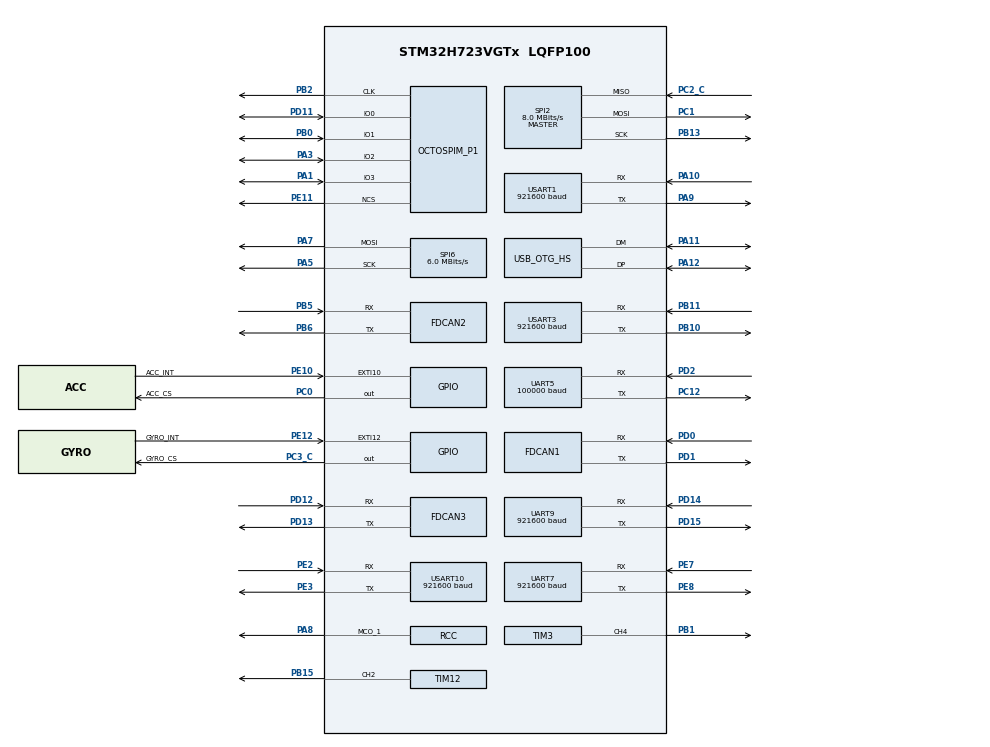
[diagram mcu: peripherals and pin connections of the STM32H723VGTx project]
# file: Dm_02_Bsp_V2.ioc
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CORTEX_M7.CPU_ICache=Enabled
CORTEX_M7.default_mode_Activation=0
Dma.Request0=UART5_RX
Dma.Request1=SPI2_RX
Dma.Request2=SPI2_TX
Dma.Request3=UART9_TX
Dma.Request4=UART9_RX
Dma.Request5=USART1_RX
Dma.Request6=USART1_TX
Dma.SPI2_RX.1.Direction=DMA_PERIPH_TO_MEMORY
Dma.SPI2_RX.1.EventEnable=DISABLE
Dma.SPI2_RX.1.FIFOMode=DMA_FIFOMODE_DISABLE
Dma.SPI2_RX.1.Instance=DMA1_Stream1
Dma.SPI2_RX.1.MemDataAlignment=DMA_MDATAALIGN_BYTE
Dma.SPI2_RX.1.MemInc=DMA_MINC_ENABLE
Dma.SPI2_RX.1.Mode=DMA_NORMAL
Dma.SPI2_RX.1.PeriphDataAlignment=DMA_PDATAALIGN_BYTE
Dma.SPI2_RX.1.PeriphInc=DMA_PINC_DISABLE
Dma.SPI2_RX.1.Polarity=HAL_DMAMUX_REQ_GEN_RISING
Dma.SPI2_RX.1.Priority=DMA_PRIORITY_VERY_HIGH
Dma.SPI2_RX.1.RequestNumber=1
Dma.SPI2_RX.1.SignalID=NONE
Dma.SPI2_RX.1.SyncEnable=DISABLE
Dma.SPI2_RX.1.SyncPolarity=HAL_DMAMUX_SYNC_NO_EVENT
Dma.SPI2_RX.1.SyncRequestNumber=1
Dma.SPI2_RX.1.SyncSignalID=NONE
Dma.SPI2_TX.2.Direction=DMA_MEMORY_TO_PERIPH
Dma.SPI2_TX.2.EventEnable=DISABLE
Dma.SPI2_TX.2.FIFOMode=DMA_FIFOMODE_DISABLE
Dma.SPI2_TX.2.Instance=DMA1_Stream2
Dma.SPI2_TX.2.MemDataAlignment=DMA_MDATAALIGN_BYTE
Dma.SPI2_TX.2.MemInc=DMA_MINC_ENABLE
Dma.SPI2_TX.2.Mode=DMA_NORMAL
Dma.SPI2_TX.2.PeriphDataAlignment=DMA_PDATAALIGN_BYTE
Dma.SPI2_TX.2.PeriphInc=DMA_PINC_DISABLE
Dma.SPI2_TX.2.Polarity=HAL_DMAMUX_REQ_GEN_RISING
Dma.SPI2_TX.2.Priority=DMA_PRIORITY_VERY_HIGH
Dma.SPI2_TX.2.RequestNumber=1
Dma.SPI2_TX.2.SignalID=NONE
Dma.SPI2_TX.2.SyncEnable=DISABLE
Dma.SPI2_TX.2.SyncPolarity=HAL_DMAMUX_SYNC_NO_EVENT
Dma.SPI2_TX.2.SyncRequestNumber=1
Dma.SPI2_TX.2.SyncSignalID=NONE
Dma.UART5_RX.0.Direction=DMA_PERIPH_TO_MEMORY
Dma.UART5_RX.0.EventEnable=DISABLE
Dma.UART5_RX.0.FIFOMode=DMA_FIFOMODE_DISABLE
Dma.UART5_RX.0.Instance=DMA1_Stream0
Dma.UART5_RX.0.MemDataAlignment=DMA_MDATAALIGN_BYTE
Dma.UART5_RX.0.MemInc=DMA_MINC_ENABLE
Dma.UART5_RX.0.Mode=DMA_NORMAL
Dma.UART5_RX.0.PeriphDataAlignment=DMA_PDATAALIGN_BYTE
Dma.UART5_RX.0.PeriphInc=DMA_PINC_DISABLE
Dma.UART5_RX.0.Polarity=HAL_DMAMUX_REQ_GEN_RISING
Dma.UART5_RX.0.Priority=DMA_PRIORITY_VERY_HIGH
Dma.UART5_RX.0.RequestNumber=1
Dma.UART5_RX.0.SignalID=NONE
Dma.UART5_RX.0.SyncEnable=DISABLE
Dma.UART5_RX.0.SyncPolarity=HAL_DMAMUX_SYNC_NO_EVENT
Dma.UART5_RX.0.SyncRequestNumber=1
Dma.UART5_RX.0.SyncSignalID=NONE
Dma.UART9_RX.4.Direction=DMA_PERIPH_TO_MEMORY
Dma.UART9_RX.4.EventEnable=DISABLE
Dma.UART9_RX.4.FIFOMode=DMA_FIFOMODE_DISABLE
Dma.UART9_RX.4.Instance=DMA1_Stream4
Dma.UART9_RX.4.MemDataAlignment=DMA_MDATAALIGN_BYTE
Dma.UART9_RX.4.MemInc=DMA_MINC_ENABLE
Dma.UART9_RX.4.Mode=DMA_NORMAL
Dma.UART9_RX.4.PeriphDataAlignment=DMA_PDATAALIGN_BYTE
Dma.UART9_RX.4.PeriphInc=DMA_PINC_DISABLE
Dma.UART9_RX.4.Polarity=HAL_DMAMUX_REQ_GEN_RISING
Dma.UART9_RX.4.Priority=DMA_PRIORITY_HIGH
Dma.UART9_RX.4.RequestNumber=1
Dma.UART9_RX.4.SignalID=NONE
Dma.UART9_RX.4.SyncEnable=DISABLE
Dma.UART9_RX.4.SyncPolarity=HAL_DMAMUX_SYNC_NO_EVENT
Dma.UART9_RX.4.SyncRequestNumber=1
Dma.UART9_RX.4.SyncSignalID=NONE
Dma.UART9_TX.3.Direction=DMA_MEMORY_TO_PERIPH
Dma.UART9_TX.3.EventEnable=DISABLE
Dma.UART9_TX.3.FIFOMode=DMA_FIFOMODE_DISABLE
Dma.UART9_TX.3.Instance=DMA1_Stream3
Dma.UART9_TX.3.MemDataAlignment=DMA_MDATAALIGN_BYTE
Dma.UART9_TX.3.MemInc=DMA_MINC_ENABLE
Dma.UART9_TX.3.Mode=DMA_NORMAL
Dma.UART9_TX.3.PeriphDataAlignment=DMA_PDATAALIGN_BYTE
Dma.UART9_TX.3.PeriphInc=DMA_PINC_DISABLE
Dma.UART9_TX.3.Polarity=HAL_DMAMUX_REQ_GEN_RISING
Dma.UART9_TX.3.Priority=DMA_PRIORITY_HIGH
Dma.UART9_TX.3.RequestNumber=1
Dma.UART9_TX.3.SignalID=NONE
Dma.UART9_TX.3.SyncEnable=DISABLE
Dma.UART9_TX.3.SyncPolarity=HAL_DMAMUX_SYNC_NO_EVENT
Dma.UART9_TX.3.SyncRequestNumber=1
Dma.UART9_TX.3.SyncSignalID=NONE
Dma.USART1_RX.5.Direction=DMA_PERIPH_TO_MEMORY
Dma.USART1_RX.5.EventEnable=DISABLE
Dma.USART1_RX.5.FIFOMode=DMA_FIFOMODE_DISABLE
Dma.USART1_RX.5.Instance=DMA1_Stream5
Dma.USART1_RX.5.MemDataAlignment=DMA_MDATAALIGN_BYTE
Dma.USART1_RX.5.MemInc=DMA_MINC_ENABLE
Dma.USART1_RX.5.Mode=DMA_NORMAL
Dma.USART1_RX.5.PeriphDataAlignment=DMA_PDATAALIGN_BYTE
Dma.USART1_RX.5.PeriphInc=DMA_PINC_DISABLE
Dma.USART1_RX.5.Polarity=HAL_DMAMUX_REQ_GEN_RISING
Dma.USART1_RX.5.Priority=DMA_PRIORITY_VERY_HIGH
Dma.USART1_RX.5.RequestNumber=1
Dma.USART1_RX.5.SignalID=NONE
Dma.USART1_RX.5.SyncEnable=DISABLE
Dma.USART1_RX.5.SyncPolarity=HAL_DMAMUX_SYNC_NO_EVENT
Dma.USART1_RX.5.SyncRequestNumber=1
Dma.USART1_RX.5.SyncSignalID=NONE
Dma.USART1_TX.6.Direction=DMA_MEMORY_TO_PERIPH
Dma.USART1_TX.6.EventEnable=DISABLE
Dma.USART1_TX.6.FIFOMode=DMA_FIFOMODE_DISABLE
Dma.USART1_TX.6.Instance=DMA1_Stream6
Dma.USART1_TX.6.MemDataAlignment=DMA_MDATAALIGN_BYTE
Dma.USART1_TX.6.MemInc=DMA_MINC_ENABLE
Dma.USART1_TX.6.Mode=DMA_NORMAL
Dma.USART1_TX.6.PeriphDataAlignment=DMA_PDATAALIGN_BYTE
Dma.USART1_TX.6.PeriphInc=DMA_PINC_DISABLE
Dma.USART1_TX.6.Polarity=HAL_DMAMUX_REQ_GEN_RISING
Dma.USART1_TX.6.Priority=DMA_PRIORITY_VERY_HIGH
Dma.USART1_TX.6.RequestNumber=1
Dma.USART1_TX.6.SignalID=NONE
Dma.USART1_TX.6.SyncEnable=DISABLE
Dma.USART1_TX.6.SyncPolarity=HAL_DMAMUX_SYNC_NO_EVENT
Dma.USART1_TX.6.SyncRequestNumber=1
Dma.USART1_TX.6.SyncSignalID=NONE
FDCAN1.AutoRetransmission=ENABLE
FDCAN1.CalculateBaudRateNominal=1000000
FDCAN1.CalculateTimeBitNominal=1000
FDCAN1.CalculateTimeQuantumNominal=25.0
FDCAN1.ExtFiltersNbr=0
FDCAN1.FrameFormat=FDCAN_FRAME_CLASSIC
FDCAN1.MessageRAMOffset=0
FDCAN1.Mode=FDCAN_MODE_NORMAL
FDCAN1.NominalPrescaler=2
FDCAN1.NominalSyncJumpWidth=6
FDCAN1.NominalTimeSeg1=32
FDCAN1.NominalTimeSeg2=7
FDCAN1.RxBuffersNbr=0
FDCAN1.RxFifo0ElmtSize=FDCAN_DATA_BYTES_8
FDCAN1.RxFifo0ElmtsNbr=64
FDCAN1.RxFifo1ElmtSize=FDCAN_DATA_BYTES_8
FDCAN1.RxFifo1ElmtsNbr=0
FDCAN1.StdFiltersNbr=2
FDCAN1.TxBuffersNbr=0
FDCAN1.TxElmtSize=FDCAN_DATA_BYTES_8
FDCAN1.TxEventsNbr=0
FDCAN1.TxFifoQueueElmtsNbr=32
FDCAN1.TxFifoQueueMode=FDCAN_TX_FIFO_OPERATION
FDCAN2.AutoRetransmission=ENABLE
FDCAN2.CalculateBaudRateNominal=1000000
FDCAN2.CalculateTimeBitNominal=1000
FDCAN2.CalculateTimeQuantumNominal=12.5
FDCAN2.DataPrescaler=1
FDCAN2.DataSyncJumpWidth=2
FDCAN2.DataTimeSeg1=13
FDCAN2.DataTimeSeg2=2
FDCAN2.ExtFiltersNbr=0
FDCAN2.FrameFormat=FDCAN_FRAME_FD_BRS
FDCAN2.MessageRAMOffset=400
FDCAN2.Mode=FDCAN_MODE_NORMAL
FDCAN2.NominalPrescaler=1
FDCAN2.NominalSyncJumpWidth=20
FDCAN2.NominalTimeSeg1=59
FDCAN2.NominalTimeSeg2=20
FDCAN2.RxBuffersNbr=0
FDCAN2.RxFifo0ElmtSize=FDCAN_DATA_BYTES_8
FDCAN2.RxFifo0ElmtsNbr=0
FDCAN2.RxFifo1ElmtSize=FDCAN_DATA_BYTES_64
FDCAN2.RxFifo1ElmtsNbr=64
FDCAN2.StdFiltersNbr=2
FDCAN2.TxBuffersNbr=0
FDCAN2.TxElmtSize=FDCAN_DATA_BYTES_64
FDCAN2.TxEventsNbr=0
FDCAN2.TxFifoQueueElmtsNbr=32
FDCAN2.TxFifoQueueMode=FDCAN_TX_FIFO_OPERATION
FDCAN3.AutoRetransmission=ENABLE
FDCAN3.CalculateBaudRateNominal=1000000
FDCAN3.CalculateTimeBitNominal=1000
FDCAN3.CalculateTimeQuantumNominal=25.0
FDCAN3.ExtFiltersNbr=0
FDCAN3.FrameFormat=FDCAN_FRAME_CLASSIC
FDCAN3.MessageRAMOffset=2140
FDCAN3.Mode=FDCAN_MODE_NORMAL
FDCAN3.NominalPrescaler=2
FDCAN3.NominalSyncJumpWidth=6
FDCAN3.NominalTimeSeg1=32
FDCAN3.NominalTimeSeg2=7
FDCAN3.RxBuffersNbr=0
FDCAN3.RxFifo0ElmtSize=FDCAN_DATA_BYTES_8
FDCAN3.RxFifo0ElmtsNbr=64
FDCAN3.RxFifo1ElmtSize=FDCAN_DATA_BYTES_8
FDCAN3.RxFifo1ElmtsNbr=0
FDCAN3.StdFiltersNbr=2
FDCAN3.TxBuffersNbr=0
FDCAN3.TxElmtSize=FDCAN_DATA_BYTES_8
FDCAN3.TxEventsNbr=0
FDCAN3.TxFifoQueueElmtsNbr=32
FDCAN3.TxFifoQueueMode=FDCAN_TX_FIFO_OPERATION
Mcu.Family=STM32H7
Mcu.Name=STM32H723VGTx
Mcu.Package=LQFP100
NVIC.DMA1_Stream0_IRQn=true\:5\:0\:false\:false\:true\:false\:true\:true
NVIC.DMA1_Stream1_IRQn=true\:5\:0\:true\:false\:true\:false\:true\:true
NVIC.DMA1_Stream2_IRQn=true\:5\:0\:true\:false\:true\:false\:true\:true
NVIC.DMA1_Stream3_IRQn=true\:5\:0\:false\:false\:true\:false\:true\:true
NVIC.DMA1_Stream4_IRQn=true\:5\:0\:false\:false\:true\:false\:true\:true
NVIC.DMA1_Stream5_IRQn=true\:0\:0\:false\:false\:true\:false\:true\:true
NVIC.DMA1_Stream6_IRQn=true\:0\:0\:false\:false\:true\:false\:true\:true
NVIC.EXTI15_10_IRQn=true\:5\:0\:false\:false\:true\:true\:true\:true
NVIC.FDCAN1_IT0_IRQn=true\:5\:0\:false\:false\:true\:true\:true\:true
NVIC.FDCAN2_IT0_IRQn=true\:5\:0\:false\:false\:true\:true\:true\:true
NVIC.FDCAN3_IT0_IRQn=true\:5\:0\:false\:false\:true\:true\:true\:true
NVIC.OTG_HS_IRQn=true\:5\:0\:false\:false\:true\:true\:true\:true
NVIC.PriorityGroup=NVIC_PRIORITYGROUP_4
NVIC.SPI2_IRQn=true\:5\:0\:false\:false\:true\:true\:true\:true
NVIC.TIM23_IRQn=true\:0\:0\:true\:false\:true\:false\:true\:true
NVIC.TIM6_DAC_IRQn=true\:7\:0\:true\:false\:true\:true\:true\:true
NVIC.TIM7_IRQn=true\:6\:0\:true\:false\:true\:true\:true\:true
NVIC.TIM8_UP_TIM13_IRQn=true\:6\:0\:false\:false\:true\:true\:true\:true
NVIC.TimeBase=TIM23_IRQn
NVIC.TimeBaseIP=TIM23
NVIC.UART5_IRQn=true\:5\:0\:false\:false\:true\:true\:true\:true
NVIC.UART7_IRQn=true\:5\:0\:false\:false\:true\:true\:true\:true
NVIC.UART9_IRQn=true\:5\:0\:true\:false\:true\:true\:true\:true
NVIC.USART10_IRQn=true\:5\:0\:false\:false\:true\:true\:true\:true
NVIC.USART1_IRQn=true\:5\:0\:false\:false\:true\:true\:true\:true
OCTOSPI2.ClockMode=HAL_OSPI_CLOCK_MODE_3
OCTOSPI2.ClockPrescaler=10
OCTOSPI2.DeviceSize=23
OCTOSPI2.DeviceType=SPI_DEVICE_FLASH
OCTOSPI2.FifoThreshold=8
OCTOSPI2.SampleShifting=HAL_OSPI_SAMPLE_SHIFTING_HALFCYCLE
PA1.Mode=OCTOSPI2_IOL_Port1L
PA1.Signal=OCTOSPIM_P1_IO3
PA10.GPIO_Speed=GPIO_SPEED_FREQ_VERY_HIGH
PA10.Mode=Asynchronous
PA10.Signal=USART1_RX
PA11.Mode=Device_Only_FS
PA11.Signal=USB_OTG_HS_DM
PA12.Mode=Device_Only_FS
PA12.Signal=USB_OTG_HS_DP
PA13(JTMS/SWDIO).Mode=Serial_Wire
PA13(JTMS/SWDIO).Signal=DEBUG_JTMS-SWDIO
PA14(JTCK/SWCLK).Mode=Serial_Wire
PA14(JTCK/SWCLK).Signal=DEBUG_JTCK-SWCLK
PA3.Mode=OCTOSPI2_IOL_Port1L
PA3.Signal=OCTOSPIM_P1_IO2
PA5.GPIO_Speed=GPIO_SPEED_FREQ_VERY_HIGH
PA5.Mode=TX_Only_Simplex_Unidirect_Master
PA5.Signal=SPI6_SCK
PA7.GPIO_Speed=GPIO_SPEED_FREQ_VERY_HIGH
PA7.Mode=TX_Only_Simplex_Unidirect_Master
PA7.Signal=SPI6_MOSI
PA8.Mode=Clock-out-1
PA8.Signal=RCC_MCO_1
PA9.GPIO_Speed=GPIO_SPEED_FREQ_VERY_HIGH
PA9.Mode=Asynchronous
PA9.Signal=USART1_TX
PB0.Mode=OCTOSPI2_IOL_Port1L
PB0.Signal=OCTOSPIM_P1_IO1
PB1.Signal=S_TIM3_CH4
PB10.GPIO_Speed=GPIO_SPEED_FREQ_VERY_HIGH
PB10.Mode=Asynchronous
PB10.Signal=USART3_TX
PB11.GPIO_Speed=GPIO_SPEED_FREQ_VERY_HIGH
PB11.Mode=Asynchronous
PB11.Signal=USART3_RX
PB13.GPIO_Speed=GPIO_SPEED_FREQ_VERY_HIGH
PB13.Mode=Full_Duplex_Master
PB13.Signal=SPI2_SCK
PB15.Signal=S_TIM12_CH2
PB2.Mode=O2_P1_CLK
PB2.Signal=OCTOSPIM_P1_CLK
PB5.GPIO_Speed=GPIO_SPEED_FREQ_VERY_HIGH
PB5.Mode=FDCAN_Activate
PB5.Signal=FDCAN2_RX
PB6.GPIO_Speed=GPIO_SPEED_FREQ_VERY_HIGH
PB6.Mode=FDCAN_Activate
PB6.Signal=FDCAN2_TX
PC0.GPIO_Label=ACC_CS
PC0.GPIO_Speed=GPIO_SPEED_FREQ_VERY_HIGH
PC0.PinState=GPIO_PIN_SET
PC0.Signal=GPIO_Output
PC1.GPIO_Speed=GPIO_SPEED_FREQ_VERY_HIGH
PC1.Mode=Full_Duplex_Master
PC1.Signal=SPI2_MOSI
PC12.GPIO_Speed=GPIO_SPEED_FREQ_VERY_HIGH
PC12.Mode=Asynchronous
PC12.Signal=UART5_TX
PC2_C.GPIO_Speed=GPIO_SPEED_FREQ_VERY_HIGH
PC2_C.Mode=Full_Duplex_Master
PC2_C.Signal=SPI2_MISO
PC3_C.GPIO_Label=GYRO_CS
PC3_C.GPIO_Speed=GPIO_SPEED_FREQ_VERY_HIGH
PC3_C.PinState=GPIO_PIN_SET
PC3_C.Signal=GPIO_Output
PD0.GPIO_Speed=GPIO_SPEED_FREQ_VERY_HIGH
PD0.Mode=FDCAN_Activate
PD0.Signal=FDCAN1_RX
PD1.GPIO_Speed=GPIO_SPEED_FREQ_VERY_HIGH
PD1.Mode=FDCAN_Activate
PD1.Signal=FDCAN1_TX
PD11.Mode=OCTOSPI2_IOL_Port1L
PD11.Signal=OCTOSPIM_P1_IO0
PD12.GPIO_Speed=GPIO_SPEED_FREQ_VERY_HIGH
PD12.Mode=FDCAN_Activate
PD12.Signal=FDCAN3_RX
PD13.GPIO_Speed=GPIO_SPEED_FREQ_VERY_HIGH
PD13.Mode=FDCAN_Activate
PD13.Signal=FDCAN3_TX
PD14.GPIO_Speed=GPIO_SPEED_FREQ_VERY_HIGH
PD14.Mode=Asynchronous
PD14.Signal=UART9_RX
PD15.GPIO_Speed=GPIO_SPEED_FREQ_VERY_HIGH
PD15.Mode=Asynchronous
PD15.Signal=UART9_TX
PD2.GPIO_Speed=GPIO_SPEED_FREQ_VERY_HIGH
PD2.Mode=Asynchronous
PD2.Signal=UART5_RX
PE10.GPIO_Label=ACC_INT
PE10.GPIO_ModeDefaultEXTI=GPIO_MODE_IT_RISING
PE10.GPIO_PuPd=GPIO_NOPULL
PE10.Signal=GPXTI10
PE11.Mode=OCTOSPI2_Port1_NCS
PE11.Signal=OCTOSPIM_P1_NCS
PE12.GPIO_Label=GYRO_INT
PE12.GPIO_ModeDefaultEXTI=GPIO_MODE_IT_RISING
PE12.GPIO_PuPd=GPIO_NOPULL
PE12.Signal=GPXTI12
PE2.GPIO_Speed=GPIO_SPEED_FREQ_VERY_HIGH
PE2.Mode=Asynchronous
PE2.Signal=USART10_RX
PE3.GPIO_Speed=GPIO_SPEED_FREQ_VERY_HIGH
PE3.Mode=Asynchronous
PE3.Signal=USART10_TX
PE7.GPIO_Speed=GPIO_SPEED_FREQ_VERY_HIGH
PE7.Mode=Asynchronous
PE7.Signal=UART7_RX
PE8.GPIO_Speed=GPIO_SPEED_FREQ_VERY_HIGH
PE8.Mode=Asynchronous
PE8.Signal=UART7_TX
PH0-OSC_IN.Mode=HSE-External-Oscillator
PH0-OSC_IN.Signal=RCC_OSC_IN
PH1-OSC_OUT.Mode=HSE-External-Oscillator
PH1-OSC_OUT.Signal=RCC_OSC_OUT
ProjectManager.HeapSize=0x200
ProjectManager.StackSize=0x400
ProjectManager.TargetToolchain=CMake
RCC.ADCFreq_Value=64000000
RCC.APB1Freq_Value=137500000
RCC.APB2Freq_Value=137500000
RCC.APB3Freq_Value=137500000
RCC.APB4Freq_Value=137500000
RCC.CortexFreq_Value=550000000
RCC.D1PPRE=RCC_APB3_DIV2
RCC.D2PPRE1=RCC_APB1_DIV2
RCC.D2PPRE2=RCC_APB2_DIV2
RCC.D3PPRE=RCC_APB4_DIV2
RCC.DIVM1=3
RCC.DIVM2=3
RCC.DIVM3=2
RCC.DIVN1=68
RCC.DIVN2=40
RCC.DIVN3=16
RCC.DIVP1=1
RCC.DIVP2=5
RCC.DIVP3=1
RCC.DIVQ1=4
RCC.DIVQ2=4
RCC.DIVQ3=4
RCC.FDCANCLockSelection=RCC_FDCANCLKSOURCE_PLL2
RCC.HCLKFreq_Value=275000000
RCC.HPRE=RCC_HCLK_DIV2
RCC.HSE_VALUE=24000000
RCC.PLL2FRACN=0
RCC.PLL3FRACN=0
RCC.PLLFRACN=6144
RCC.PLLSourceVirtual=RCC_PLLSOURCE_HSE
RCC.SPI123CLockSelection=RCC_SPI123CLKSOURCE_PLL2
RCC.SPI6CLockSelection=RCC_SPI6CLKSOURCE_HSE
RCC.SYSCLKFreq_VALUE=550000000
RCC.SYSCLKSource=RCC_SYSCLKSOURCE_PLLCLK
RCC.USBCLockSelection=RCC_USBCLKSOURCE_PLL3
RCC.USBFreq_Value=48000000
SH.S_TIM12_CH2.0=TIM12_CH2,PWM Generation2 CH2
SH.S_TIM3_CH4.0=TIM3_CH4,PWM Generation4 CH4
SPI2.BaudRatePrescaler=SPI_BAUDRATEPRESCALER_8
SPI2.CLKPhase=SPI_PHASE_2EDGE
SPI2.CLKPolarity=SPI_POLARITY_HIGH
SPI2.CalculateBaudRate=8.0 MBits/s
SPI2.DataSize=SPI_DATASIZE_8BIT
SPI2.Direction=SPI_DIRECTION_2LINES
SPI2.Mode=SPI_MODE_MASTER
SPI2.VirtualType=VM_MASTER
SPI6.BaudRatePrescaler=SPI_BAUDRATEPRESCALER_4
SPI6.CLKPhase=SPI_PHASE_2EDGE
SPI6.CalculateBaudRate=6.0 MBits/s
SPI6.DataSize=SPI_DATASIZE_8BIT
SPI6.Direction=SPI_DIRECTION_2LINES_TXONLY
SPI6.Mode=SPI_MODE_MASTER
SPI6.VirtualType=VM_MASTER
STMicroelectronics.X-CUBE-ALGOBUILD.1.5.0.LibraryCcDSPOoLibraryJjDSPOoLibrary=true
STMicroelectronics.X-CUBE-ALGOBUILD.1.5.0.LibraryCcMotionOoLibrariesJjMotionOoLibraries=true
TIM12.Channel-PWM\ Generation2\ CH2=TIM_CHANNEL_2
TIM12.Period=249
TIM12.Prescaler=274
TIM12.Pulse-PWM\ Generation2\ CH2=0
TIM13.AutoReloadPreload=TIM_AUTORELOAD_PRELOAD_ENABLE
TIM13.Period=54999
TIM13.Prescaler=4
TIM3.AutoReloadPreload=TIM_AUTORELOAD_PRELOAD_ENABLE
TIM3.Channel-PWM\ Generation4\ CH4=TIM_CHANNEL_4
TIM3.Period=999
TIM3.Prescaler=274
TIM3.Pulse-PWM\ Generation4\ CH4=0
TIM6.AutoReloadPreload=TIM_AUTORELOAD_PRELOAD_ENABLE
TIM6.Period=9999
TIM6.Prescaler=274
TIM7.AutoReloadPreload=TIM_AUTORELOAD_PRELOAD_ENABLE
TIM7.Period=999
TIM7.Prescaler=274
UART5.BaudRate=100000
UART5.Parity=PARITY_EVEN
UART5.StopBits=UART_STOPBITS_2
UART5.WordLength=WORDLENGTH_9B
UART7.BaudRate=921600
UART9.BaudRate=921600
USART1.BaudRate=921600
USART1.VirtualMode-Asynchronous=VM_ASYNC
USART10.BaudRate=921600
USART10.VirtualMode=VM_ASYNC
USART3.BaudRate=921600
USART3.VirtualMode-Asynchronous=VM_ASYNC
USB_DEVICE.CLASS_NAME_HS=CDC
USB_DEVICE.VirtualMode=Cdc
USB_DEVICE.VirtualModeHS=Cdc_HS
USB_OTG_HS.VirtualMode-Device_Only_FS=Device_Only_FS
USB_OTG_HS.dma_enable-Device_Only_FS=DISABLE
VP_CRC_VS_CRC.Mode=CRC_Activate
VP_MEMORYMAP_VS_MEMORYMAP.Mode=CurAppReg
VP_OCTOSPI2_VS_quad.Mode=quad_mode
VP_STMicroelectronics.X-CUBE-ALGOBUILD_VS_DSPOoLibraryJjLibrary_1.5.0_1.5.0.Mode=DSPOoLibraryJjLibrary
VP_STMicroelectronics.X-CUBE-ALGOBUILD_VS_MotionOoLibrariesJjLibrary_1.5.0_1.5.0.Mode=MotionOoLibrariesJjLibrary
VP_SYS_VS_tim23.Mode=TIM23
VP_TIM13_VS_ClockSourceINT.Mode=Enable_Timer
VP_TIM6_VS_ClockSourceINT.Mode=Enable_Timer
VP_TIM7_VS_ClockSourceINT.Mode=Enable_Timer
VP_USB_DEVICE_VS_USB_DEVICE_CDC_HS.Mode=CDC_HS
board=custom

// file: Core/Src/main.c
/* USER CODE BEGIN Header */
/**
  ******************************************************************************
  * @file           : main.c
  * @brief          : Main program body
  ******************************************************************************
  * @attention
  *
  * Copyright (c) 2026 STMicroelectronics.
  * All rights reserved.
  *
  * This software is licensed under terms that can be found in the LICENSE file
  * in the root directory of this software component.
  * If no LICENSE file comes with this software, it is provided AS-IS.
  *
  ******************************************************************************
  */
/* USER CODE END Header */
#include "main.h"
#include "crc.h"
#include "dma.h"
#include "fdcan.h"
#include "octospi.h"
#include "spi.h"
#include "tim.h"
#include "usart.h"
#include "usb_device.h"
#include "gpio.h"

/* USER CODE BEGIN Includes */
#include "Application.h"
/* USER CODE END Includes */

void SystemClock_Config(void);
void PeriphCommonClock_Config(void);

int main(void)
{

  /* Enable the CPU Cache */

  /* Enable I-Cache---------------------------------------------------------*/
  SCB_EnableICache();

  /* MCU Configuration--------------------------------------------------------*/

  /* Reset of all peripherals, Initializes the Flash interface and the Systick. */
  HAL_Init();

  /* Configure the system clock */
  SystemClock_Config();

  /* Configure the peripherals common clocks */
  PeriphCommonClock_Config();

  /* Initialize all configured peripherals */
  MX_GPIO_Init();
  MX_DMA_Init();
  MX_FDCAN1_Init();
  MX_FDCAN2_Init();
  MX_FDCAN3_Init();
  MX_OCTOSPI2_Init();
  MX_USART3_UART_Init();
  MX_USART10_UART_Init();
  MX_USB_DEVICE_Init();
  MX_SPI2_Init();
  MX_SPI6_Init();
  MX_TIM3_Init();
  MX_TIM12_Init();
  MX_USART1_UART_Init();
  MX_UART7_Init();
  MX_TIM13_Init();
  MX_UART5_Init();
  MX_TIM7_Init();
  MX_TIM6_Init();
  MX_UART9_Init();
  MX_CRC_Init();
  /* USER CODE BEGIN 2 */
  Application_Init();
  HAL_TIM_Base_Start_IT(&htim7);
  /* USER CODE END 2 */

  /* Infinite loop */
  /* USER CODE BEGIN WHILE */
  while (1)
  {
    Application_Loop();
    /* USER CODE END WHILE */

  }
}

void SystemClock_Config(void)
{
  RCC_OscInitTypeDef RCC_OscInitStruct = {0};
  RCC_ClkInitTypeDef RCC_ClkInitStruct = {0};

  /** Supply configuration update enable
  */
  HAL_PWREx_ConfigSupply(PWR_LDO_SUPPLY);

  /** Configure the main internal regulator output voltage
  */
  __HAL_PWR_VOLTAGESCALING_CONFIG(PWR_REGULATOR_VOLTAGE_SCALE0);

  while(!__HAL_PWR_GET_FLAG(PWR_FLAG_VOSRDY)) {}

  /** Initializes the RCC Oscillators according to the specified parameters
  * in the RCC_OscInitTypeDef structure.
  */
  RCC_OscInitStruct.OscillatorType = RCC_OSCILLATORTYPE_HSI|RCC_OSCILLATORTYPE_HSE;
  RCC_OscInitStruct.HSEState = RCC_HSE_ON;
  RCC_OscInitStruct.HSIState = RCC_HSI_DIV1;
  RCC_OscInitStruct.HSICalibrationValue = 64;
  RCC_OscInitStruct.PLL.PLLState = RCC_PLL_ON;
  RCC_OscInitStruct.PLL.PLLSource = RCC_PLLSOURCE_HSE;
  RCC_OscInitStruct.PLL.PLLM = 3;
  RCC_OscInitStruct.PLL.PLLN = 68;
  RCC_OscInitStruct.PLL.PLLP = 1;
  RCC_OscInitStruct.PLL.PLLQ = 4;
  RCC_OscInitStruct.PLL.PLLR = 2;
  RCC_OscInitStruct.PLL.PLLRGE = RCC_PLL1VCIRANGE_3;
  RCC_OscInitStruct.PLL.PLLVCOSEL = RCC_PLL1VCOWIDE;
  RCC_OscInitStruct.PLL.PLLFRACN = 6144;
  if (HAL_RCC_OscConfig(&RCC_OscInitStruct) != HAL_OK)
  {
    Error_Handler();
  }

  /** Initializes the CPU, AHB and APB buses clocks
  */
  RCC_ClkInitStruct.ClockType = RCC_CLOCKTYPE_HCLK|RCC_CLOCKTYPE_SYSCLK
                              |RCC_CLOCKTYPE_PCLK1|RCC_CLOCKTYPE_PCLK2
                              |RCC_CLOCKTYPE_D3PCLK1|RCC_CLOCKTYPE_D1PCLK1;
  RCC_ClkInitStruct.SYSCLKSource = RCC_SYSCLKSOURCE_PLLCLK;
  RCC_ClkInitStruct.SYSCLKDivider = RCC_SYSCLK_DIV1;
  RCC_ClkInitStruct.AHBCLKDivider = RCC_HCLK_DIV2;
  RCC_ClkInitStruct.APB3CLKDivider = RCC_APB3_DIV2;
  RCC_ClkInitStruct.APB1CLKDivider = RCC_APB1_DIV2;
  RCC_ClkInitStruct.APB2CLKDivider = RCC_APB2_DIV2;
  RCC_ClkInitStruct.APB4CLKDivider = RCC_APB4_DIV2;

  if (HAL_RCC_ClockConfig(&RCC_ClkInitStruct, FLASH_LATENCY_3) != HAL_OK)
  {
    Error_Handler();
  }
  HAL_RCC_MCOConfig(RCC_MCO1, RCC_MCO1SOURCE_HSI, RCC_MCODIV_1);
}

void PeriphCommonClock_Config(void)
{
  RCC_PeriphCLKInitTypeDef PeriphClkInitStruct = {0};

  /** Initializes the peripherals clock
  */
  PeriphClkInitStruct.PeriphClockSelection = RCC_PERIPHCLK_SPI2|RCC_PERIPHCLK_FDCAN;
  PeriphClkInitStruct.PLL2.PLL2M = 3;
  PeriphClkInitStruct.PLL2.PLL2N = 40;
  PeriphClkInitStruct.PLL2.PLL2P = 5;
  PeriphClkInitStruct.PLL2.PLL2Q = 4;
  PeriphClkInitStruct.PLL2.PLL2R = 2;
  PeriphClkInitStruct.PLL2.PLL2RGE = RCC_PLL2VCIRANGE_3;
  PeriphClkInitStruct.PLL2.PLL2VCOSEL = RCC_PLL2VCOWIDE;
  PeriphClkInitStruct.PLL2.PLL2FRACN = 0;
  PeriphClkInitStruct.Spi123ClockSelection = RCC_SPI123CLKSOURCE_PLL2;
  PeriphClkInitStruct.FdcanClockSelection = RCC_FDCANCLKSOURCE_PLL2;
  if (HAL_RCCEx_PeriphCLKConfig(&PeriphClkInitStruct) != HAL_OK)
  {
    Error_Handler();
  }
}

void HAL_TIM_PeriodElapsedCallback(TIM_HandleTypeDef *htim)
{
  /* USER CODE BEGIN Callback 0 */
  Application_Timer_Callback(htim);
  /* USER CODE END Callback 0 */
  if (htim->Instance == TIM23)
  {
    HAL_IncTick();
  }
}

void Error_Handler(void)
{
  __disable_irq();
  while (1)
  {
  }
}
